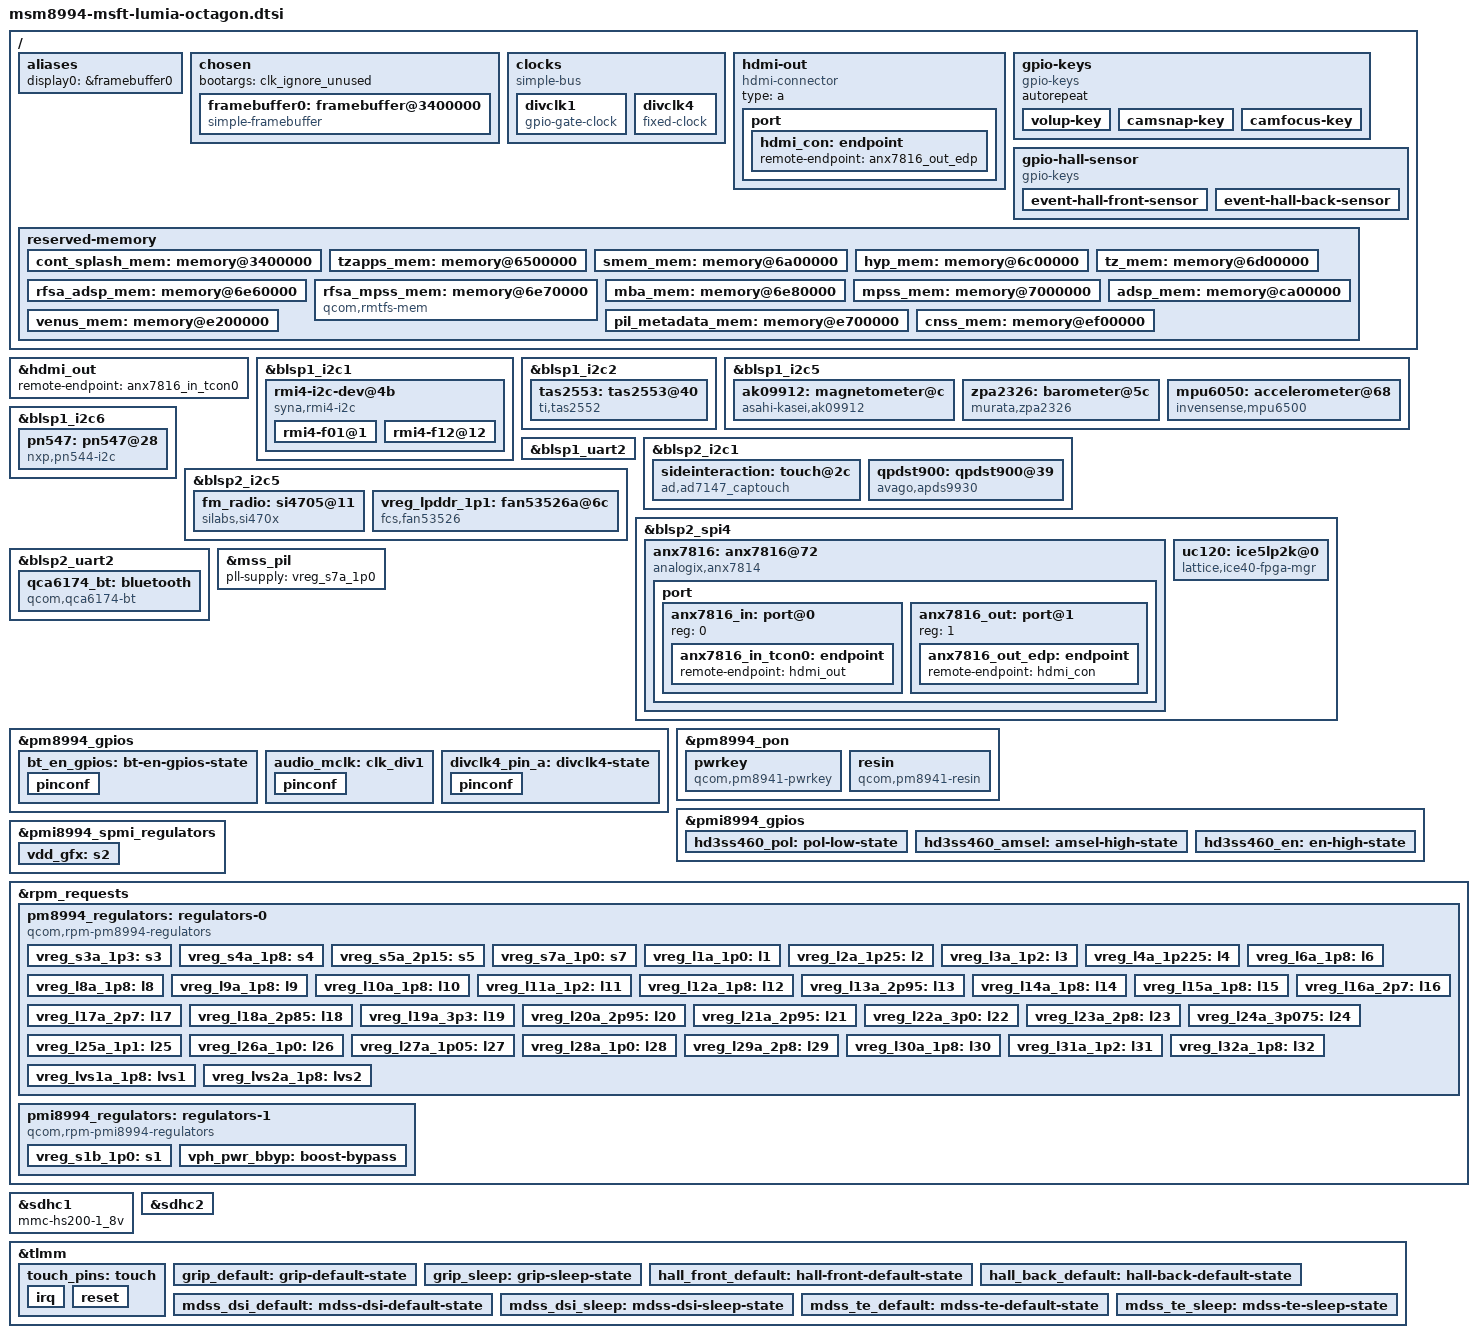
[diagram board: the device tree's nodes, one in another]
// SPDX-License-Identifier: BSD-3-Clause
/*
 * Common Board Device Tree for
 * Microsoft Mobile MSM8994 Octagon Platforms
 *
 * Copyright (c) 2020, Konrad Dybcio
 * Copyright (c) 2020, Gustave Monce <gustave.monce@outlook.com>
 * Copyright (c) 2024, Girjeu Efim <efimgirjeu3@gmail.com>
 */

#include "pm8994.dtsi"
#include "pmi8994.dtsi"
#include <dt-bindings/gpio/gpio.h>
#include <dt-bindings/input/gpio-keys.h>
#include <dt-bindings/pinctrl/qcom,pmic-gpio.h>

/*
 * Delete all generic (msm8994.dtsi) reserved
 * memory mappings which are different in this device.
 */
/delete-node/ &adsp_mem;
/delete-node/ &audio_mem;
/delete-node/ &mba_mem;
/delete-node/ &mpss_mem;
/delete-node/ &peripheral_region;
/delete-node/ &res_hyp_mem;
/delete-node/ &rmtfs_mem;
/delete-node/ &smem_mem;

/* cont_splash_mem has different memory mapping */
/delete-node/ &cont_splash_mem;

/* disabled on downstream, conflicts with cont_splash_mem */
/delete-node/ &dfps_data_mem;

/ {
	/*
	 * Most Lumia 950/XL users use GRUB or lk2nd to load their kernels,
	 * hence there is no need for msm-id and friends.
	 */
	aliases {
		display0 = &framebuffer0;
	};

	chosen {
		bootargs = "clk_ignore_unused";
		#address-cells = <2>;
		#size-cells = <2>;
		ranges;


		/* Use display framebuffer setup by the UEFI XBL bootloader for simplefb */
		framebuffer0: framebuffer@3400000 {
			compatible = "simple-framebuffer";
			reg = <0x0 0x03400000 0x0 0xc00000>;
			width = <1080>;
			height = <1920>;
			stride = <(1080 * 4)>;
			format = "a8r8g8b8";
			/*
			* That's a lot of clocks, but it's necessary due
			* to unused clk cleanup & no panel driver yet..
			*/
			clocks = <&mmcc MDSS_AHB_CLK>,
				 <&mmcc MDSS_AXI_CLK>,
				 <&mmcc MDSS_VSYNC_CLK>,
				 <&mmcc MDSS_MDP_CLK>,
				 <&mmcc MDSS_BYTE0_CLK>,
				 <&mmcc MDSS_PCLK0_CLK>,
				 <&mmcc MDSS_ESC0_CLK>;
			power-domains = <&mmcc MDSS_GDSC>;
		};
};

	clocks {
			compatible = "simple-bus";

		divclk1: divclk1 {
			compatible = "gpio-gate-clock";
			#clock-cells = <0>;

			clocks = <&rpmcc RPM_SMD_DIV_CLK1>;
			enable-gpios = <&pm8994_gpios 15 0>;
			
			pinctrl-names = "default";
			pinctrl-0 = <&audio_mclk>;
		};
	};

	clocks {
		divclk4: divclk4 {
			compatible = "fixed-clock";
			#clock-cells = <0>;

			clock-frequency = <32768>;
			clock-output-names = "divclk4";

			pinctrl-names = "default";
			pinctrl-0 = <&divclk4_pin_a>;
		};
	};

	hdmi-out {
		compatible = "hdmi-connector";
		type = "a";

		port {
			hdmi_con: endpoint {
				remote-endpoint = <&anx7816_out_edp>;
			};
		};
	};

	gpio-keys {
		compatible = "gpio-keys";
		autorepeat;

		volup-key {
			label = "Volume Up";
			gpios = <&pm8994_gpios 3 GPIO_ACTIVE_LOW>;
			linux,input-type = <1>;
			linux,code = <KEY_VOLUMEUP>;
			wakeup-source;
			debounce-interval = <15>;
		};

		camsnap-key {
			label = "Camera Snapshot";
			gpios = <&pm8994_gpios 4 GPIO_ACTIVE_LOW>;
			linux,input-type = <1>;
			linux,code = <KEY_CAMERA>;
			wakeup-source;
			debounce-interval = <15>;
		};

		camfocus-key {
			label = "Camera Focus";
			gpios = <&pm8994_gpios 5 GPIO_ACTIVE_LOW>;
			linux,input-type = <1>;
			linux,code = <KEY_VOLUMEUP>;
			wakeup-source;
			debounce-interval = <15>;
		};
	};

	gpio-hall-sensor {
		compatible = "gpio-keys";

		pinctrl-names = "default";
		pinctrl-0 = <&hall_front_default &hall_back_default>;

		label = "GPIO Hall Effect Sensor";

		event-hall-front-sensor {
			label = "Hall Effect Front Sensor";
			gpios = <&tlmm 42 GPIO_ACTIVE_HIGH>;
			linux,input-type = <EV_SW>;
			linux,code = <SW_LID>;
			linux,can-disable;
		};

		event-hall-back-sensor {
			label = "Hall Effect Back Sensor";
			gpios = <&tlmm 75 GPIO_ACTIVE_HIGH>;
			linux,input-type = <EV_SW>;
			linux,code = <SW_MACHINE_COVER>;
			linux,can-disable;
		};
	};

	reserved-memory {
		/*
		 * This device being a WP platform has a very different
		 * memory layout than other Android based devices.
		 * This memory layout is directly copied from the original
		 * device UEFI firmware, and adapted based on observations
		 * using JTAG for the Qualcomm Peripheral Image regions.
		 */

		cont_splash_mem: memory@3400000 {
			reg = <0 0x03400000 0 0xc00000>;
			no-map;
		};

		tzapps_mem: memory@6500000 {
			reg = <0 0x06500000 0 0x500000>;
			no-map;
		};

		smem_mem: memory@6a00000 {
			reg = <0 0x06a00000 0 0x200000>;
			no-map;
		};

		hyp_mem: memory@6c00000 {
			reg = <0 0x06c00000 0 0x100000>;
			no-map;
		};

		tz_mem: memory@6d00000 {
			reg = <0 0x06d00000 0 0x160000>;
			no-map;
		};

		/*
		 * Value obtained from the device original ACPI DSDT table
		 * ADSP_EFS
		 */
		rfsa_adsp_mem: memory@6e60000 {
			reg = <0 0x06e60000 0 0x10000>;
			no-map;
		};

		/* Value obtained from the device original ACPI DSDT table */
		rfsa_mpss_mem: memory@6e70000 {
			compatible = "qcom,rmtfs-mem";
			reg = <0 0x06e70000 0 0x10000>;
			no-map;

			qcom,client-id = <1>;
		};

		/*
		 * Value obtained from the device original ACPI DSDT table
		 * MPSS_EFS / SBL
		 *
		 * Here goes MBA
		 */
		mba_mem: memory@6e80000 {
			reg = <0 0x06e80000 0 0x180000>;
			no-map;
		};

		/*
		 * Peripheral Image loader region begin!
		 * The region reserved for pil is 0x7000000-0xef00000
		 */

		/* Here goes AMSS */
		mpss_mem: memory@7000000 {
			reg = <0 0x07000000 0 0x5a00000>;
			no-map;
		};

		/* Here goes ADSP */
		adsp_mem: memory@ca00000 {
			reg = <0 0x0ca00000 0 0x1800000>;
			no-map;
		};

		/* Here goes VSS */
		venus_mem: memory@e200000 {
			reg = <0 0x0e200000 0 0x500000>;
			no-map;
		};

		/* Here goes PIL metadata */
		pil_metadata_mem: memory@e700000 {
			reg = <0 0x0e700000 0 0x4000>;
			no-map;
		};

		//memory@e704000 {
		//	reg = <0 0x0e704000 0 0x7fc000>;
		//	no-map;
		//};
		/* Peripheral Image loader region end */

		cnss_mem: memory@ef00000 {
			reg = <0 0x0ef00000 0 0x300000>;
			no-map;
		};
	};
};


/*
 * When cci_i2c buses are brought up,
 * 3 camera sensors need to be added as follows:
 *
 * &cci_i2c0 {
 *  // H1400/1 Ducati (FF CAM FPC) (Front) (Sharp)
 *	ffc_sensor: ffc-sensor@20 {
 *		compatible = "nokia,smia";
 *
 *		reg = <0x20>;
 *
 *		reset-gpios = <&tlmm 104 GPIO_ACTIVE_HIGH>;
 *		vana-supply = <&vreg_l17a_2p7>;
 *
 *		clocks = <&CAM_MCLK2 0>;
 *		clock-frequency = <xxxxxx>;
 *		...
 *	};
 *
 *  // H1000/1 Siiri (IRIS CAM FPC) (Iris) (Toshiba) (T4KE1)
 *	iris_sensor: iris-sensor@6c {
 *		compatible = "nokia,smia";
 *
 *		reg = <0x6c>;
 *
 *		reset-gpios = <&tlmm 102 GPIO_ACTIVE_HIGH>;
 *		vana-supply = <&vreg_l17a_2p7>;
 *
 *		clocks = <&CAM_MCLK1 0>;
 *		clock-frequency = <xxxxxx>;
 *		...
 *	};
 *
 * Also on the same bus: 
 * Austrianmicrosystems AS3638 triple LED flash controller (No driver available)
 * };
 *
 * &cci_i2c1 {
 *  // N1400/1 Hill (Sub board FPC) (Rear) (Sony) (IMX230)
 *	rfc_sensor: rfc-sensor@20 {
 *		compatible = "nokia,smia";
 *
 *		reg = <0x20>;
 *
 *		reset-gpios = <&tlmm 106 GPIO_ACTIVE_HIGH>; // This is either 105 or 106
 *		vana-supply = <&vreg_l29a_2p8>;
 *
 *		clocks = <&CAM_MCLK0 0>;
 *		clock-frequency = <xxxxxx>;
 *		link-frequencies = ...;
 *
 *		port {
 *			smiapp_ep: endpoint {
 *				data-lanes = <... ...>;
 *				remote-endpoint = <&...>;
 *			};
 *		};
 *	};
 * };
 */

&hdmi_out {
	remote-endpoint = <&anx7816_in_tcon0>;
};

&framebuffer0 {
	width = <1080>;
	height = <1920>;
	stride = <(1080 * 4)>;
};

&blsp1_i2c1 {
	status = "okay";

	rmi4-i2c-dev@4b {
		compatible = "syna,rmi4-i2c";
		reg = <0x4b>;
		#address-cells = <1>;
		#size-cells = <0>;

		interrupt-parent = <&tlmm>;
		interrupts = <77 IRQ_TYPE_EDGE_FALLING>;
		
		vdd-supply = <&vreg_l22a_3p0>;
		reset-gpios = <&tlmm 38 GPIO_ACTIVE_LOW>;

		pinctrl-names = "default";
		pinctrl-0 = <&touch_pins>;


		rmi4-f01@1 {
			reg = <0x01>;
			syna,nosleep-mode = <1>;
		};

		rmi4-f12@12 {
			reg = <0x12>;
			syna,sensor-type = <1>;
			syna,clip-x-low = <0>;
			syna,clip-x-high = <1440>;
			syna,clip-y-low = <0>;
			syna,clip-y-high = <2560>;
		};
	};
};

&blsp1_i2c2 {
	status = "okay";

	/*
	 * This device uses the Texas Instruments TAS2553, however the TAS2552 driver
	 * seems to work here. In the future a proper driver might need to
	 * be written for this device.
	 */
	tas2553: tas2553@40 {
		compatible = "ti,tas2552";
		reg = <0x40>;

		vbat-supply = <&vph_pwr>;
		iovdd-supply = <&vreg_s4a_1p8>;
		avdd-supply = <&vreg_s4a_1p8>;

		enable-gpio = <&pm8994_gpios 12 GPIO_ACTIVE_HIGH>;
	};
};

&blsp1_i2c5 {
	status = "okay";

	ak09912: magnetometer@c {
		compatible = "asahi-kasei,ak09912";
		reg = <0xc>;

		interrupt-parent = <&tlmm>;
		interrupts = <26 IRQ_TYPE_EDGE_RISING>;

		vdd-supply = <&vreg_l18a_2p85>;
		vid-supply = <&vreg_lvs2a_1p8>;
	};

	zpa2326: barometer@5c {
		compatible = "murata,zpa2326";
		reg = <0x5c>;

		interrupt-parent = <&tlmm>;
		interrupts = <74 IRQ_TYPE_EDGE_RISING>;

		vdd-supply = <&vreg_lvs2a_1p8>;
	};

	mpu6050: accelerometer@68 {
		compatible = "invensense,mpu6500";
		reg = <0x68>;

		interrupt-parent = <&tlmm>;
		interrupts = <64 IRQ_TYPE_EDGE_RISING>;

		vdd-supply = <&vreg_lvs2a_1p8>;
		vddio-supply = <&vreg_lvs2a_1p8>;
	};
};

&blsp1_i2c6 {
	status = "okay";

	pn547: pn547@28 {
		compatible = "nxp,pn544-i2c";

		reg = <0x28>;

		interrupt-parent = <&tlmm>;
		interrupts = <29 IRQ_TYPE_EDGE_RISING>;

		enable-gpios = <&tlmm 30 GPIO_ACTIVE_HIGH>;
		firmware-gpios = <&tlmm 94 GPIO_ACTIVE_HIGH>;
	};
};

&blsp1_uart2 {
	status = "okay";
};

&blsp2_i2c1 {
	status = "okay";

	sideinteraction: touch@2c {
		compatible = "ad,ad7147_captouch";
		reg = <0x2c>;

		pinctrl-names = "default", "sleep";
		pinctrl-0 = <&grip_default>;
		pinctrl-1 = <&grip_sleep>;

		interrupts = <&tlmm 96 IRQ_TYPE_EDGE_FALLING>;

		button_num = <8>;
		touchpad_num = <0>;
		wheel_num = <0>;
		slider_num = <0>;

		vcc-supply = <&vreg_l18a_2p85>;
	};

	/*
	 * The QPDS-T900/QPDS-T930 is a customized part built for Nokia
	 * by Avago. It is very similar to the Avago APDS-9930 with some
	 * minor differences. In the future a proper driver might need to
	 * be written for this device. For now this works fine.
	 */
	qpdst900: qpdst900@39 {
		compatible = "avago,apds9930";
		reg = <0x39>;

		interrupt-parent = <&tlmm>;
		interrupts = <40 IRQ_TYPE_EDGE_FALLING>;
	};
};

&blsp2_i2c5 {
	status = "okay";

	fm_radio: si4705@11 {
		compatible = "silabs,si470x";
		reg = <0x11>;

		interrupt-parent = <&tlmm>;
		interrupts = <9 IRQ_TYPE_EDGE_FALLING>;
		reset-gpios = <&tlmm 93 GPIO_ACTIVE_HIGH>;
	};

	vreg_lpddr_1p1: fan53526a@6c {
		compatible = "fcs,fan53526";
		reg = <0x6c>;

		regulator-min-microvolt = <1100000>;
		regulator-max-microvolt = <1100000>;
		vin-supply = <&vph_pwr>;
		fcs,suspend-voltage-selector = <1>;
		regulator-always-on; /* Turning off DDR power doesn't sound good. */
	};

	/* ANX7816 HDMI bridge (needs MDSS HDMI) */
};

&blsp2_spi4 {
	status = "okay";

	/*
	 * This device uses the Analogix ANX7816, however the ANX7816 driver
	 * seems to work here. In the future a proper driver might need to
	 * be written for this device.
	 */
	anx7816: anx7816@72 {
		compatible = "analogix,anx7814";

		reg = <0x72>;

		interrupt-parent = <&tlmm>;
		interrupts = <41 IRQ_TYPE_EDGE_FALLING>;

		hpd-gpios = <&pmi8994_gpios 2 GPIO_ACTIVE_HIGH>;
		pd-gpios = <&pmi8994_gpios 6 GPIO_ACTIVE_HIGH>;
		reset-gpios = <&pmi8994_gpios 7 GPIO_ACTIVE_HIGH>;

		dvdd10-supply = <&vreg_l27a_1p05>;

		port {
			#address-cells = <1>;
			#size-cells = <0>;

			anx7816_in: port@0 {
				reg = <0>;
				anx7816_in_tcon0: endpoint {
					remote-endpoint = <&hdmi_out>;
				};
			};

			anx7816_out: port@1 {
				reg = <1>;
				anx7816_out_edp: endpoint {
					remote-endpoint = <&hdmi_con>;
				};
			};
		};
	};
	/*
	 * This device is a Lattice UC120 USB-C PD PHY.
	 * It is actually a Lattice iCE40 FPGA pre-programmed by
	 * the device firmware with a specific bitstream
	 * enabling USB Type C PHY functionality.
	 * Communication is done via a proprietary protocol over SPI.
	 *
	 * TODO: Once a proper driver is available, replace this.
	 */
	uc120: ice5lp2k@0 {
		compatible = "lattice,ice40-fpga-mgr";
		reg = <0>;
		spi-max-frequency = <5000000>;
		cdone-gpios = <&tlmm 95 GPIO_ACTIVE_HIGH>;
		reset-gpios = <&pmi8994_gpios 4 GPIO_ACTIVE_LOW>;
	};
};

&blsp2_uart2 {
	status = "okay";
	
	qca6174_bt: bluetooth {
		compatible = "qcom,qca6174-bt";
		pinctrl-names = "default";
		pinctrl-0 = <&bt_en_gpios>;

		enable-gpios = <&pm8994_gpios 19 GPIO_ACTIVE_HIGH>;
		vddio-supply = <&vreg_s4a_1p8>;
		clocks = <&divclk4>;
		interrupt-parent = <&tlmm>;
		interrupts = <19 IRQ_TYPE_EDGE_RISING>;
		qcom,local-bd-address-broken;
	};
};

&mss_pil {
	status = "okay";
	pll-supply = <&vreg_s7a_1p0>;
};

&pm8994_gpios {
	gpio-line-names = 
		"NC",
		"WLC_EN", /* GPIO_02 */
		"VOL_UP_N", /* GPIO_03 */
		"SNAPSHOT_N", /* GPIO_04 */
		"FOCUS_N", /* GPIO_05 */
		"NC",
		"NFC_PWR_REQ", /* GPIO_07 */
		"SD_CARD_DET", /* GPIO_08 */
		"WLAN_LDO_3V_CTRL", /* GPIO_09 */
		"NFC_CLK_REQ", /* GPIO_10 */
		"WLAN_PWR_REQ", /* GPIO_11 */
		"IHF_LEFT_EN", /* GPIO_12 */
		"VCONN_OUT_EN", /* GPIO_13 */
		"WLC_DET", /* GPIO_14 */
		"DIVCLK1_CDC", /* GPIO_15 */
		"PMI_CLK", /* GPIO_16 */
		"DP_PD_CLK", /* GPIO_17 */
		"DIVCLK4", /* GPIO_18 */
		"BT_EN", /* GPIO_19 */
		"PMI_SPON", /* GPIO_20 */
		"BUA_PMI8994"; /* GPIO_21 */

	bt_en_gpios: bt-en-gpios-state {
		pinconf {
			pins = "gpio19";
			function = PMIC_GPIO_FUNC_NORMAL;
			output-low;
			power-source = <PM8994_GPIO_S4>;
			qcom,drive-strength = <PMIC_GPIO_STRENGTH_LOW>;
			bias-pull-down;
		};
	};

	audio_mclk: clk_div1 {
		pinconf {
			pins = "gpio15";
			function = PMIC_GPIO_FUNC_FUNC1;
			power-source = <PM8994_GPIO_S4>;
		};
	};


	divclk4_pin_a: divclk4-state {
		pinconf {
			pins = "gpio18";
			function = PMIC_GPIO_FUNC_FUNC2;
			power-source = <PM8994_GPIO_S4>;
			bias-disable;
		};
	};
};

&pm8994_pon {
	pwrkey {
		compatible = "qcom,pm8941-pwrkey";
		interrupts = <0 8 0 IRQ_TYPE_EDGE_BOTH>;
		debounce = <15625>;
		linux,code = <KEY_POWER>;
	};

	resin {
		compatible = "qcom,pm8941-resin";
		interrupts = <0 8 1 IRQ_TYPE_EDGE_BOTH>;
		debounce = <15625>;
		linux,code = <KEY_VOLUMEDOWN>;
	};
};

&pmi8994_gpios {
	gpio-line-names =
		"NC",
		"DP_HPD", /* GPIO_2 */
		"NC",
		"PD_EN", /* GPIO_4 */
		"TYPEC_VBUS_EN", /* GPIO_5 */
		"DP_CHIP_PD", /* GPIO_6 */
		"DP_EN", /* GPIO_7 */
		"SS_POL", /* GPIO_8 */
		"SS_MUX_SEL", /* GPIO_9 */
		"SS_MUX_EN"; /* GPIO_10 */
	pinctrl-0 = <&hd3ss460_pol &hd3ss460_amsel &hd3ss460_en>;
	pinctrl-names = "default";

	/*
	 * This device uses a TI HD3SS460 Type-C MUX
	 * As this device has no driver currently,
	 * the configuration for USB Face Up is set-up here.
	 *
	 * TODO: remove once a driver is available
	 * TODO: add VBUS GPIO 5
	 */
	hd3ss460_pol: pol-low-state {
		pins = "gpio8";
		function = PMIC_GPIO_FUNC_NORMAL;
		qcom,drive-strength = <3>;
		bias-pull-down;
	};

	hd3ss460_amsel: amsel-high-state {
		pins = "gpio9";
		function = PMIC_GPIO_FUNC_NORMAL;
		qcom,drive-strength = <1>;
		bias-pull-up;
	};

	hd3ss460_en: en-high-state {
		pins = "gpio10";
		function = PMIC_GPIO_FUNC_NORMAL;
		qcom,drive-strength = <1>;
		bias-pull-up;
	};
};

&pmi8994_spmi_regulators {
	vdd_gfx: s2 {
		regulator-min-microvolt = <980000>;
		regulator-max-microvolt = <980000>;
	};
};

&rpm_requests {
	/* These values were taken from the original firmware ACPI tables */
	pm8994_regulators: regulators-0 {
		compatible = "qcom,rpm-pm8994-regulators";

		vdd_s1-supply = <&vph_pwr>;
		vdd_s2-supply = <&vph_pwr>;
		vdd_s3-supply = <&vph_pwr>;
		vdd_s4-supply = <&vph_pwr>;
		vdd_s5-supply = <&vph_pwr>;
		vdd_s6-supply = <&vph_pwr>;
		vdd_s7-supply = <&vph_pwr>;
		vdd_s8-supply = <&vph_pwr>;
		vdd_s9-supply = <&vph_pwr>;
		vdd_s10-supply = <&vph_pwr>;
		vdd_s11-supply = <&vph_pwr>;
		vdd_s12-supply = <&vph_pwr>;
		vdd_l1-supply = <&vreg_s1b_1p0>;
		vdd_l2_l26_l28-supply = <&vreg_s3a_1p3>;
		vdd_l3_l11-supply = <&vreg_s3a_1p3>;
		vdd_l4_l27_l31-supply = <&vreg_s3a_1p3>;
		vdd_l5_l7-supply = <&vreg_s5a_2p15>;
		vdd_l6_l12_l32-supply = <&vreg_s5a_2p15>;
		vdd_l8_l16_l30-supply = <&vph_pwr>;
		vdd_l9_l10_l18_l22-supply = <&vph_pwr_bbyp>;
		vdd_l13_l19_l23_l24-supply = <&vph_pwr_bbyp>;
		vdd_l14_l15-supply = <&vreg_s5a_2p15>;
		vdd_l17_l29-supply = <&vph_pwr_bbyp>;
		vdd_l20_l21-supply = <&vph_pwr_bbyp>;
		vdd_l25-supply = <&vreg_s5a_2p15>;
		vdd_lvs1_2-supply = <&vreg_s4a_1p8>;

		/* S1, S2, S6 and S12 are managed by RPMPD */

		vreg_s3a_1p3: s3 {
			regulator-min-microvolt = <1300000>;
			regulator-max-microvolt = <1300000>;
			regulator-allow-set-load;
			regulator-system-load = <300000>;
		};

		vreg_s4a_1p8: s4 {
			regulator-min-microvolt = <1800000>;
			regulator-max-microvolt = <1800000>;
			regulator-allow-set-load;
			regulator-always-on;
			regulator-system-load = <325000>;
		};

		vreg_s5a_2p15: s5 {
			regulator-min-microvolt = <2150000>;
			regulator-max-microvolt = <2150000>;
			regulator-allow-set-load;
			regulator-system-load = <325000>;
		};

		vreg_s7a_1p0: s7 {
			regulator-min-microvolt = <1000000>;
			regulator-max-microvolt = <1000000>;
		};

		/*
		 * S8 - SPMI-managed VDD_APC0
		 * S9, S10 and S11 (the main one) - SPMI-managed VDD_APC1
		 */

		vreg_l1a_1p0: l1 {
			regulator-min-microvolt = <1000000>;
			regulator-max-microvolt = <1000000>;
		};

		vreg_l2a_1p25: l2 {
			regulator-min-microvolt = <1250000>;
			regulator-max-microvolt = <1250000>;
			regulator-allow-set-load;
			regulator-system-load = <4160>;
		};

		vreg_l3a_1p2: l3 {
			regulator-min-microvolt = <1200000>;
			regulator-max-microvolt = <1200000>;
			regulator-always-on;
			regulator-allow-set-load;
			regulator-system-load = <80000>;
		};

		vreg_l4a_1p225: l4 {
			regulator-min-microvolt = <1225000>;
			regulator-max-microvolt = <1225000>;
		};

		/* L5 is inaccessible from RPM */

		vreg_l6a_1p8: l6 {
			regulator-min-microvolt = <1800000>;
			regulator-max-microvolt = <1800000>;
			regulator-allow-set-load;
			regulator-system-load = <1000>;
		};

		/* L7 is inaccessible from RPM */

		vreg_l8a_1p8: l8 {
			regulator-min-microvolt = <1800000>;
			regulator-max-microvolt = <1800000>;
		};

		vreg_l9a_1p8: l9 {
			regulator-min-microvolt = <1800000>;
			regulator-max-microvolt = <1800000>;
		};

		vreg_l10a_1p8: l10 {
			regulator-min-microvolt = <1800000>;
			regulator-max-microvolt = <1800000>;
		};

		vreg_l11a_1p2: l11 {
			regulator-min-microvolt = <1200000>;
			regulator-max-microvolt = <1200000>;
			regulator-always-on;
			regulator-allow-set-load;
			regulator-system-load = <35000>;
		};

		vreg_l12a_1p8: l12 {
			regulator-min-microvolt = <1800000>;
			regulator-max-microvolt = <1800000>;
			regulator-always-on;
			regulator-allow-set-load;
			regulator-system-load = <50000>;
		};

		vreg_l13a_2p95: l13 {
			regulator-min-microvolt = <1850000>;
			regulator-max-microvolt = <2950000>;
			regulator-always-on;
			regulator-allow-set-load;
			regulator-system-load = <22000>;
		};

		vreg_l14a_1p8: l14 {
			regulator-min-microvolt = <1800000>;
			regulator-max-microvolt = <1800000>;
			regulator-always-on;
			regulator-allow-set-load;
			regulator-system-load = <52000>;
		};

		vreg_l15a_1p8: l15 {
			regulator-min-microvolt = <1800000>;
			regulator-max-microvolt = <1800000>;
		};

		vreg_l16a_2p7: l16 {
			regulator-min-microvolt = <2700000>;
			regulator-max-microvolt = <2700000>;
		};

		vreg_l17a_2p7: l17 {
			regulator-min-microvolt = <2800000>;
			regulator-max-microvolt = <2800000>;
			regulator-always-on;
			regulator-allow-set-load;
			regulator-system-load = <300000>;
		};

		vreg_l18a_2p85: l18 {
			regulator-min-microvolt = <2850000>;
			regulator-max-microvolt = <2850000>;
			regulator-always-on;
			regulator-allow-set-load;
			regulator-system-load = <600000>;
		};

		vreg_l19a_3p3: l19 {
			regulator-min-microvolt = <3300000>;
			regulator-max-microvolt = <3300000>;
			regulator-always-on;
			regulator-allow-set-load;
			regulator-system-load = <500000>;
		};

		vreg_l20a_2p95: l20 {
			regulator-min-microvolt = <2950000>;
			regulator-max-microvolt = <2950000>;
			regulator-always-on;
			regulator-boot-on;
			regulator-allow-set-load;
			regulator-system-load = <570000>;
		};

		vreg_l21a_2p95: l21 {
			regulator-min-microvolt = <2950000>;
			regulator-max-microvolt = <2950000>;
			regulator-always-on;
			regulator-allow-set-load;
			regulator-system-load = <800000>;
		};

		vreg_l22a_3p0: l22 {
			regulator-min-microvolt = <3000000>;
			regulator-max-microvolt = <3000000>;
			regulator-always-on;
			regulator-allow-set-load;
			regulator-system-load = <150000>;
		};

		vreg_l23a_2p8: l23 {
			regulator-min-microvolt = <2850000>;
			regulator-max-microvolt = <2850000>;
			regulator-always-on;
			regulator-allow-set-load;
			regulator-system-load = <80000>;
		};

		vreg_l24a_3p075: l24 {
			regulator-min-microvolt = <3075000>;
			regulator-max-microvolt = <3150000>;
			regulator-allow-set-load;
			regulator-system-load = <5800>;
		};

		vreg_l25a_1p1: l25 {
			regulator-min-microvolt = <1150000>;
			regulator-max-microvolt = <1150000>;
			regulator-always-on;
			regulator-allow-set-load;
			regulator-system-load = <80000>;
		};

		vreg_l26a_1p0: l26 {
			regulator-min-microvolt = <1000000>;
			regulator-max-microvolt = <1000000>;
		};

		vreg_l27a_1p05: l27 {
			regulator-min-microvolt = <1000000>;
			regulator-max-microvolt = <1000000>;
			regulator-always-on;
			regulator-allow-set-load;
			regulator-system-load = <500000>;
		};

		vreg_l28a_1p0: l28 {
			regulator-min-microvolt = <1000000>;
			regulator-max-microvolt = <1000000>;
			regulator-always-on;
			regulator-allow-set-load;
			regulator-system-load = <26000>;
		};

		vreg_l29a_2p8: l29 {
			regulator-min-microvolt = <2850000>;
			regulator-max-microvolt = <2850000>;
			regulator-always-on;
			regulator-allow-set-load;
			regulator-system-load = <80000>;
		};

		vreg_l30a_1p8: l30 {
			regulator-min-microvolt = <1800000>;
			regulator-max-microvolt = <1800000>;
			regulator-always-on;
			regulator-allow-set-load;
			regulator-system-load = <2500>;
		};

		vreg_l31a_1p2: l31 {
			regulator-min-microvolt = <1200000>;
			regulator-max-microvolt = <1200000>;
			regulator-always-on;
			regulator-allow-set-load;
			regulator-system-load = <600000>;
		};

		vreg_l32a_1p8: l32 {
			regulator-min-microvolt = <1800000>;
			regulator-max-microvolt = <1800000>;
		};

		vreg_lvs1a_1p8: lvs1 { };

		vreg_lvs2a_1p8: lvs2 { };
	};

	pmi8994_regulators: regulators-1 {
		compatible = "qcom,rpm-pmi8994-regulators";

		vdd_s1-supply = <&vph_pwr>;
		vdd_bst_byp-supply = <&vph_pwr>;

		vreg_s1b_1p0: s1 {
			regulator-min-microvolt = <1025000>;
			regulator-max-microvolt = <1025000>;
		};

		/* S2 & S3 - VDD_GFX */

		vph_pwr_bbyp: boost-bypass {
			regulator-min-microvolt = <3300000>;
			regulator-max-microvolt = <3300000>;
		};
	};
};

&sdhc1 {
	status = "okay";

	/*
	 * This device is shipped with HS400 capabable eMMCs
	 * However various brands have been used in various product batches,
	 * including a Samsung eMMC (BGND3R) which features a quirk with HS400.
	 * Set the speed to HS200 as a safety measure.
	 */
	mmc-hs200-1_8v;
};

&sdhc2 {
	status = "okay";

	pinctrl-names = "default", "sleep";
	pinctrl-0 = <&sdc2_clk_on &sdc2_cmd_on &sdc2_data_on>;
	pinctrl-1 = <&sdc2_clk_off &sdc2_cmd_off &sdc2_data_off>;

	vmmc-supply = <&vreg_l21a_2p95>;
	vqmmc-supply = <&vreg_l13a_2p95>;

	cd-gpios = <&pm8994_gpios 8 GPIO_ACTIVE_LOW>;
};

&tlmm {
	gpio-line-names = 
		"NC",
		"NC",
		"TOUCH_I2C_DATA", /* GPIO_2 */
		"TOUCH_I2C_CLK", /* GPIO_3 */
		"NC",
		"NC",
		"AUDIO_I2C_DATA", /* GPIO_6 */
		"AUDIO_I2C_CLK", /* GPIO_7 */
		"FLASH_EN", /* GPIO_8 */
		"FM_INT_N", /* GPIO_9 */
		"DISPLAY_TEARING", /* GPIO_10 */
		"NC",
		"TORCH_EN", /* GPIO_12 */
		"CAM_MCLK0", /* GPIO_13 */
		"CAM_MCLK1", /* GPIO_14 */
		"CAM_MCLK2", /* GPIO_15 */
		"NC",
		"CCI0_I2C_DATA", /* GPIO_17 */
		"CCI0_I2C_CLK", /* GPIO_18 */
		"CCI1_I2C_DATA", /* GPIO_19 */
		"CCI1_I2C_CLK", /* GPIO_20 */
		"NC",
		"CPLUG_DET", /* GPIO_22 */
		"SENSORS1_I2C_DATA", /* GPIO_23 */
		"SENSORS1_I2C_CLK", /* GPIO_24 */
		"NC",
		"MAGNETOMETER_INT", /* GPIO_26 */
		"NFC_I2C_DATA", /* GPIO_27 */
		"NFC_I2C_CLK", /* GPIO_28 */
		"NFC_IRQ", /* GPIO_29 */
		"NFC_ENABLE", /* GPIO_30 */
		"CEC", /* GPIO_31 */
		"SCL", /* GPIO_32 */
		"SDA", /* GPIO_33 */
		"HDMI_HOT_PLUG_DET", /* GPIO_34 */
		"PCIE_WL_RST_N", /* GPIO_35 */
		"PCIE_WL_CLK_REQ_N", /* GPIO_36 */
		"PCIE_WL_WAKE_N", /* GPIO_37 */
		"TOUCH_RESET_N", /* GPIO_38 */
		"GRIP_RST_N", /* GPIO_39 */
		"PROX_INT_N", /* GPIO_40 */
		"DP_INT", /* GPIO_41 */
		"HAL_SWITCH", /* GPIO_42 */
		"SENSORS2_I2C_DATA", /* GPIO_43 */
		"SENSORS2_I2C_CLK", /* GPIO_44 */
		"BT_UART_RXD", /* GPIO_45 */
		"BT_UART_TXD", /* GPIO_46 */
		"BT_UART_RTS", /* GPIO_47 */
		"BT_UART_CTS", /* GPIO_48 */
		"UIM2_DATA", /* GPIO_49 */
		"UIM2_CLK", /* GPIO_50 */
		"UIM2_RST", /* GPIO_51 */
		"NC",
		"SPI_MOSI", /* GPIO_53 */
		"SPI_MISO", /* GPIO_54 */
		"SPI_CS_N", /* GPIO_55 */
		"SPI_CLK", /* GPIO_56 */
		"TOUCH EXT CLK", /* GPIO_57 */
		"IHF_I2S_SCKL", /* GPIO_58 */
		"IHF_I2S_WS", /* GPIO_59 */
		"IHF_I2S_DIN_L", /* GPIO_60 */
		"NC",
		"IHF_I2S_DOUT", /* GPIO_62 */
		"NC",
		"ACCEL_GYRO_INT", /* GPIO_64 */
		"FM_I2S_CLK", /* GPIO_65 */
		"FM_I2S_SYNC", /* GPIO_66 */
		"FM_I2S_DATA", /* GPIO_67 */
		"CODEC_RESET_N", /* GPIO_68 */
		"NC",
		"SLIMBUS_CDC_CLK", /* GPIO_70 */
		"SLIMBUS_CDC_DATA", /* GPIO_71 */
		"CODEC_INT1", /* GPIO_72 */
		"CODEC_INT2", /* GPIO_73 */
		"BARO_INT_N", /* GPIO_74 */
		"HAL_SWITCH_2", /* GPIO_75 */
		"NC",
		"TOUCH_INT_N", /* GPIO_77 */
		"DISPLAY_RESET_N", /* GPIO_78 */
		"BT_PCM_CLK", /* GPIO_79 */
		"BT_PCM_SYNC", /* GPIO_80 */
		"BT_PCM_DOUT", /* GPIO_81 */
		"BT_PCM_DIN", /* GPIO_82 */
		"APPS_I2C_DATA", /* GPIO_83 */
		"APPS_I2C_CLK", /* GPIO_84 */
		"NC",
		"NC",
		"NC",
		"NC",
		"NC",
		"NC",
		"CAM_UKNW0", /* GPIO_91 */
		"CAM_UKNW1", /* GPIO_92 */
		"FM_RESET_N", /* GPIO_93 */
		"NFC_DWL_REQ", /* GPIO_94 */
		"PD_INT_N", /* GPIO_95 */
		"GRIP_INT_N", /* GPIO_96 */
		"UIM1_DATA", /* GPIO_97 */
		"UIM1_CLK", /* GPIO_98 */
		"UIM1_RST", /* GPIO_99 */
		"NC",
		"BUA_PMI8994", /* GPIO_101 */
		"IRIS_CAM_RES_N", /* GPIO_102 */
		"NC",
		"XSHUTDOWN", /* GPIO_104 */
		"CAM_UKNW3", /* GPIO_105 */
		"CAM_UKNW4", /* GPIO_106 */
		"NC",
		"NC",
		"NC",
		"NC",
		"NC",
		"NC",
		"WLAN_EN", /* GPIO_113 */
		"NC",
		"GRFC_0", /* GPIO_115 */
		"GRFC_1", /* GPIO_116 */
		"GRFC_2", /* GPIO_117 */
		"GRFC_3", /* GPIO_118 */
		"NC",
		"NC",
		"BOM_DET_0", /* GPIO_121 */
		"NC",
		"NC",
		"NC",
		"RF_PA_ON/GRFC_10", /* GPIO_125 */
		"NC",
		"NC",
		"NC",
		"EXT_GPS_LNA_EN", /* GPIO_129 */
		"GPS_TX_AGGRESSOR", /* GPIO_130 */
		"GSM_TX1_PHASE_D0", /* GPIO_131 */
		"NC",
		"GRFC_15", /* GPIO_133 */
		"LTE_SYNC", /* GPIO_134 */
		"LTE_PRI", /* GPIO_135 */
		"RFFE1_CLK", /* GPIO_136 */
		"RFFE1_DATA", /* GPIO_137 */
		"RFFE2_CLK", /* GPIO_138 */
		"RFFE2_DATA", /* GPIO_139 */
		"RFFE3_CLK", /* GPIO_140 */
		"RFFE3_DATA"; /* GPIO_141 */

	touch_pins: touch {
		irq {
			pins = "gpio77";
			function = "gpio";
			drive-strength = <8>;
			bias-pull-up;
			input-enable;
		};
		reset {
			pins = "gpio38";
			function = "gpio";
			drive-strength = <8>;
			bias-disable;
			output-high;
		};
	};

	grip_default: grip-default-state {
		pins = "gpio39";
		function = "gpio";
		drive-strength = <6>;
		bias-pull-down;
	};

	grip_sleep: grip-sleep-state {
		pins = "gpio39";
		function = "gpio";
		drive-strength = <2>;
		bias-pull-down;
	};

	hall_front_default: hall-front-default-state {
		pins = "gpio42";
		function = "gpio";
		drive-strength = <2>;
		bias-disable;
	};

	hall_back_default: hall-back-default-state {
		pins = "gpio75";
		function = "gpio";
		drive-strength = <2>;
		bias-disable;
	};

	mdss_dsi_default: mdss-dsi-default-state {
		pins = "gpio78";
		function = "gpio";
		drive-strength = <8>;
		bias-disable;
	};

	mdss_dsi_sleep: mdss-dsi-sleep-state {
		pins = "gpio78";
		function = "gpio";
		drive-strength = <2>;
		bias-pull-down;
	};

	mdss_te_default: mdss-te-default-state {
		pins = "gpio10";
		function = "mdp_vsync";
		drive-strength = <2>;
		bias-pull-down;
	};

	mdss_te_sleep: mdss-te-sleep-state {
		pins = "gpio10";
		function = "mdp_vsync";
		drive-strength = <2>;
		bias-pull-down;
	};
};
